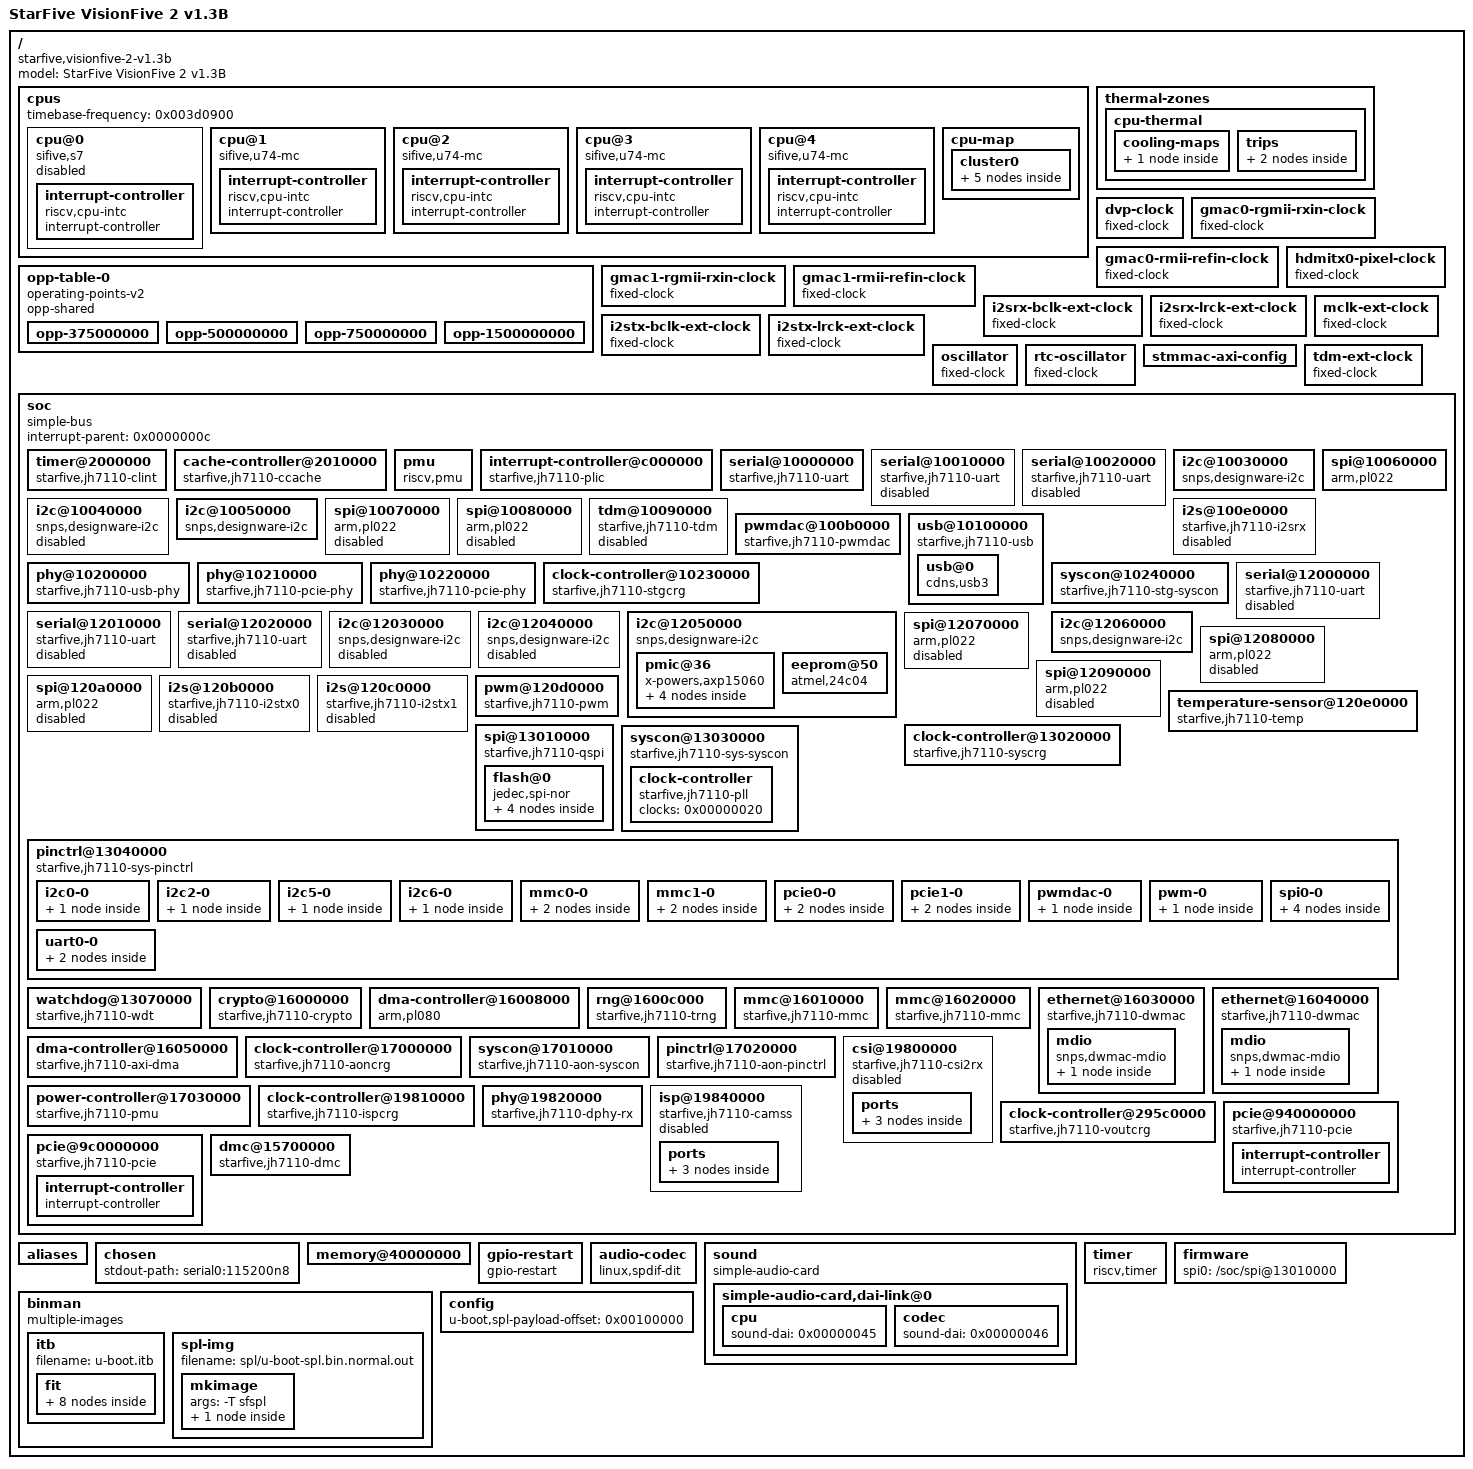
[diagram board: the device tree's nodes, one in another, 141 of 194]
//这个玩意来自于mainline
/dts-v1/;
// magic:		0xd00dfeed
// totalsize:		0xb18d (45453)
// off_dt_struct:	0x78
// off_dt_strings:	0x9234
// off_mem_rsvmap:	0x28
// version:		17
// last_comp_version:	16
// boot_cpuid_phys:	0x0
// size_dt_strings:	0xf59
// size_dt_struct:	0x91bc

/ {
    compatible = "starfive,visionfive-2-v1.3b", "starfive,jh7110";
    #address-cells = <0x00000002>;
    #size-cells = <0x00000002>;
    model = "StarFive VisionFive 2 v1.3B";
    cpus {
        #address-cells = <0x00000001>;
        #size-cells = <0x00000000>;
        timebase-frequency = <0x003d0900>;
        bootph-pre-ram;
        phandle = <0x00000047>;
        cpu@0 {
            compatible = "sifive,s7", "riscv";
            reg = <0x00000000>;
            device_type = "cpu";
            i-cache-block-size = <0x00000040>;
            i-cache-sets = <0x00000040>;
            i-cache-size = <0x00004000>;
            next-level-cache = <0x00000001>;
            riscv,isa = "rv64imac_zba_zbb";
            riscv,isa-base = "rv64i";
            riscv,isa-extensions = "i", "m", "a", "c", "zba", "zbb", "zicntr", "zicsr", "zifencei", "zihpm";
            status = "disabled";
            phandle = <0x00000005>;
            interrupt-controller {
                compatible = "riscv,cpu-intc";
                interrupt-controller;
                #interrupt-cells = <0x00000001>;
                bootph-pre-ram;
                phandle = <0x0000000d>;
            };
        };
        cpu@1 {
            compatible = "sifive,u74-mc", "riscv";
            reg = <0x00000001>;
            d-cache-block-size = <0x00000040>;
            d-cache-sets = <0x00000040>;
            d-cache-size = <0x00008000>;
            d-tlb-sets = <0x00000001>;
            d-tlb-size = <0x00000028>;
            device_type = "cpu";
            i-cache-block-size = <0x00000040>;
            i-cache-sets = <0x00000040>;
            i-cache-size = <0x00008000>;
            i-tlb-sets = <0x00000001>;
            i-tlb-size = <0x00000028>;
            mmu-type = "riscv,sv39";
            next-level-cache = <0x00000001>;
            riscv,isa = "rv64imafdc_zba_zbb";
            riscv,isa-base = "rv64i";
            riscv,isa-extensions = "i", "m", "a", "f", "d", "c", "zba", "zbb", "zicntr", "zicsr", "zifencei", "zihpm";
            tlb-split;
            operating-points-v2 = <0x00000002>;
            clocks = <0x00000003 0x00000001>;
            clock-names = "cpu";
            #cooling-cells = <0x00000002>;
            cpu-supply = <0x00000004>;
            phandle = <0x00000006>;
            interrupt-controller {
                compatible = "riscv,cpu-intc";
                interrupt-controller;
                #interrupt-cells = <0x00000001>;
                bootph-pre-ram;
                phandle = <0x0000000e>;
            };
        };
        cpu@2 {
            compatible = "sifive,u74-mc", "riscv";
            reg = <0x00000002>;
            d-cache-block-size = <0x00000040>;
            d-cache-sets = <0x00000040>;
            d-cache-size = <0x00008000>;
            d-tlb-sets = <0x00000001>;
            d-tlb-size = <0x00000028>;
            device_type = "cpu";
            i-cache-block-size = <0x00000040>;
            i-cache-sets = <0x00000040>;
            i-cache-size = <0x00008000>;
            i-tlb-sets = <0x00000001>;
            i-tlb-size = <0x00000028>;
            mmu-type = "riscv,sv39";
            next-level-cache = <0x00000001>;
            riscv,isa = "rv64imafdc_zba_zbb";
            riscv,isa-base = "rv64i";
            riscv,isa-extensions = "i", "m", "a", "f", "d", "c", "zba", "zbb", "zicntr", "zicsr", "zifencei", "zihpm";
            tlb-split;
            operating-points-v2 = <0x00000002>;
            clocks = <0x00000003 0x00000001>;
            clock-names = "cpu";
            #cooling-cells = <0x00000002>;
            cpu-supply = <0x00000004>;
            phandle = <0x00000007>;
            interrupt-controller {
                compatible = "riscv,cpu-intc";
                interrupt-controller;
                #interrupt-cells = <0x00000001>;
                bootph-pre-ram;
                phandle = <0x0000000f>;
            };
        };
        cpu@3 {
            compatible = "sifive,u74-mc", "riscv";
            reg = <0x00000003>;
            d-cache-block-size = <0x00000040>;
            d-cache-sets = <0x00000040>;
            d-cache-size = <0x00008000>;
            d-tlb-sets = <0x00000001>;
            d-tlb-size = <0x00000028>;
            device_type = "cpu";
            i-cache-block-size = <0x00000040>;
            i-cache-sets = <0x00000040>;
            i-cache-size = <0x00008000>;
            i-tlb-sets = <0x00000001>;
            i-tlb-size = <0x00000028>;
            mmu-type = "riscv,sv39";
            next-level-cache = <0x00000001>;
            riscv,isa = "rv64imafdc_zba_zbb";
            riscv,isa-base = "rv64i";
            riscv,isa-extensions = "i", "m", "a", "f", "d", "c", "zba", "zbb", "zicntr", "zicsr", "zifencei", "zihpm";
            tlb-split;
            operating-points-v2 = <0x00000002>;
            clocks = <0x00000003 0x00000001>;
            clock-names = "cpu";
            #cooling-cells = <0x00000002>;
            cpu-supply = <0x00000004>;
            phandle = <0x00000008>;
            interrupt-controller {
                compatible = "riscv,cpu-intc";
                interrupt-controller;
                #interrupt-cells = <0x00000001>;
                bootph-pre-ram;
                phandle = <0x00000010>;
            };
        };
        cpu@4 {
            compatible = "sifive,u74-mc", "riscv";
            reg = <0x00000004>;
            d-cache-block-size = <0x00000040>;
            d-cache-sets = <0x00000040>;
            d-cache-size = <0x00008000>;
            d-tlb-sets = <0x00000001>;
            d-tlb-size = <0x00000028>;
            device_type = "cpu";
            i-cache-block-size = <0x00000040>;
            i-cache-sets = <0x00000040>;
            i-cache-size = <0x00008000>;
            i-tlb-sets = <0x00000001>;
            i-tlb-size = <0x00000028>;
            mmu-type = "riscv,sv39";
            next-level-cache = <0x00000001>;
            riscv,isa = "rv64imafdc_zba_zbb";
            riscv,isa-base = "rv64i";
            riscv,isa-extensions = "i", "m", "a", "f", "d", "c", "zba", "zbb", "zicntr", "zicsr", "zifencei", "zihpm";
            tlb-split;
            operating-points-v2 = <0x00000002>;
            clocks = <0x00000003 0x00000001>;
            clock-names = "cpu";
            #cooling-cells = <0x00000002>;
            cpu-supply = <0x00000004>;
            phandle = <0x00000009>;
            interrupt-controller {
                compatible = "riscv,cpu-intc";
                interrupt-controller;
                #interrupt-cells = <0x00000001>;
                bootph-pre-ram;
                phandle = <0x00000011>;
            };
        };
        cpu-map {
            cluster0 {
                core0 {
                    cpu = <0x00000005>;
                };
                core1 {
                    cpu = <0x00000006>;
                };
                core2 {
                    cpu = <0x00000007>;
                };
                core3 {
                    cpu = <0x00000008>;
                };
                core4 {
                    cpu = <0x00000009>;
                };
            };
        };
    };
    opp-table-0 {
        compatible = "operating-points-v2";
        opp-shared;
        phandle = <0x00000002>;
        opp-375000000 {
            opp-hz = <0x00000000 0x165a0bc0>;
            opp-microvolt = <0x000c3500>;
        };
        opp-500000000 {
            opp-hz = <0x00000000 0x1dcd6500>;
            opp-microvolt = <0x000c3500>;
        };
        opp-750000000 {
            opp-hz = <0x00000000 0x2cb41780>;
            opp-microvolt = <0x000c3500>;
        };
        opp-1500000000 {
            opp-hz = <0x00000000 0x59682f00>;
            opp-microvolt = <0x000fde80>;
        };
    };
    thermal-zones {
        cpu-thermal {
            polling-delay-passive = <0x000000fa>;
            polling-delay = <0x00003a98>;
            thermal-sensors = <0x0000000a>;
            cooling-maps {
                map0 {
                    trip = <0x0000000b>;
                    cooling-device = <0x00000006 0xffffffff 0xffffffff 0x00000007 0xffffffff 0xffffffff 0x00000008 0xffffffff 0xffffffff 0x00000009 0xffffffff 0xffffffff>;
                };
            };
            trips {
                cpu-alert0 {
                    temperature = <0x00014c08>;
                    hysteresis = <0x000007d0>;
                    type = "passive";
                    phandle = <0x0000000b>;
                };
                cpu-crit {
                    temperature = <0x000186a0>;
                    hysteresis = <0x000007d0>;
                    type = "critical";
                };
            };
        };
    };
    dvp-clock {
        compatible = "fixed-clock";
        clock-output-names = "dvp_clk";
        #clock-cells = <0x00000000>;
        clock-frequency = <0x046cf710>;
        phandle = <0x0000003a>;
    };
    gmac0-rgmii-rxin-clock {
        compatible = "fixed-clock";
        clock-output-names = "gmac0_rgmii_rxin";
        #clock-cells = <0x00000000>;
        clock-frequency = <0x07735940>;
        bootph-pre-ram;
        phandle = <0x00000035>;
    };
    gmac0-rmii-refin-clock {
        compatible = "fixed-clock";
        clock-output-names = "gmac0_rmii_refin";
        #clock-cells = <0x00000000>;
        clock-frequency = <0x02faf080>;
        bootph-pre-ram;
        phandle = <0x00000034>;
    };
    gmac1-rgmii-rxin-clock {
        compatible = "fixed-clock";
        clock-output-names = "gmac1_rgmii_rxin";
        #clock-cells = <0x00000000>;
        clock-frequency = <0x07735940>;
        bootph-pre-ram;
        phandle = <0x00000027>;
    };
    gmac1-rmii-refin-clock {
        compatible = "fixed-clock";
        clock-output-names = "gmac1_rmii_refin";
        #clock-cells = <0x00000000>;
        clock-frequency = <0x02faf080>;
        bootph-pre-ram;
        phandle = <0x00000026>;
    };
    hdmitx0-pixel-clock {
        compatible = "fixed-clock";
        clock-output-names = "hdmitx0_pixelclk";
        #clock-cells = <0x00000000>;
        clock-frequency = <0x11b3dc40>;
        phandle = <0x0000003d>;
    };
    i2srx-bclk-ext-clock {
        compatible = "fixed-clock";
        clock-output-names = "i2srx_bclk_ext";
        #clock-cells = <0x00000000>;
        clock-frequency = <0x00bb8000>;
        phandle = <0x00000019>;
    };
    i2srx-lrck-ext-clock {
        compatible = "fixed-clock";
        clock-output-names = "i2srx_lrck_ext";
        #clock-cells = <0x00000000>;
        clock-frequency = <0x0002ee00>;
        phandle = <0x0000001a>;
    };
    i2stx-bclk-ext-clock {
        compatible = "fixed-clock";
        clock-output-names = "i2stx_bclk_ext";
        #clock-cells = <0x00000000>;
        clock-frequency = <0x00bb8000>;
        phandle = <0x00000023>;
    };
    i2stx-lrck-ext-clock {
        compatible = "fixed-clock";
        clock-output-names = "i2stx_lrck_ext";
        #clock-cells = <0x00000000>;
        clock-frequency = <0x0002ee00>;
        phandle = <0x00000024>;
    };
    mclk-ext-clock {
        compatible = "fixed-clock";
        clock-output-names = "mclk_ext";
        #clock-cells = <0x00000000>;
        clock-frequency = <0x00bb8000>;
        phandle = <0x00000018>;
    };
    oscillator {
        compatible = "fixed-clock";
        clock-output-names = "osc";
        #clock-cells = <0x00000000>;
        clock-frequency = <0x016e3600>;
        bootph-pre-ram;
        phandle = <0x00000020>;
    };
    rtc-oscillator {
        compatible = "fixed-clock";
        clock-output-names = "rtc_osc";
        #clock-cells = <0x00000000>;
        clock-frequency = <0x00008000>;
        phandle = <0x00000036>;
    };
    stmmac-axi-config {
        snps,lpi_en;
        snps,wr_osr_lmt = <0x0000000f>;
        snps,rd_osr_lmt = <0x0000000f>;
        snps,blen = <0x00000100 0x00000080 0x00000040 0x00000020 0x00000000 0x00000000 0x00000000>;
        phandle = <0x00000030>;
    };
    tdm-ext-clock {
        compatible = "fixed-clock";
        clock-output-names = "tdm_ext";
        #clock-cells = <0x00000000>;
        clock-frequency = <0x02ee0000>;
        phandle = <0x00000016>;
    };
    soc {
        compatible = "simple-bus";
        interrupt-parent = <0x0000000c>;
        #address-cells = <0x00000002>;
        #size-cells = <0x00000002>;
        ranges;
        bootph-pre-ram;
        timer@2000000 {
            compatible = "starfive,jh7110-clint", "sifive,clint0";
            reg = <0x00000000 0x02000000 0x00000000 0x00010000>;
            interrupts-extended = <0x0000000d 0x00000003 0x0000000d 0x00000007 0x0000000e 0x00000003 0x0000000e 0x00000007 0x0000000f 0x00000003 0x0000000f 0x00000007 0x00000010 0x00000003 0x00000010 0x00000007 0x00000011 0x00000003 0x00000011 0x00000007>;
            bootph-pre-ram;
            phandle = <0x00000048>;
        };
        cache-controller@2010000 {
            compatible = "starfive,jh7110-ccache", "sifive,ccache0", "cache";
            reg = <0x00000000 0x02010000 0x00000000 0x00004000>;
            interrupts = <0x00000001 0x00000003 0x00000004 0x00000002>;
            cache-block-size = <0x00000040>;
            cache-level = <0x00000002>;
            cache-sets = <0x00000800>;
            cache-size = <0x00200000>;
            cache-unified;
            phandle = <0x00000001>;
        };
        pmu {
            compatible = "riscv,pmu";
            riscv,event-to-mhpmcounters = <0x00000005 0x00000006 0x00000018>;
            riscv,event-to-mhpmevent = <0x00000005 0x00000000 0x00004000 0x00000006 0x00000000 0x00004001>;
            riscv,raw-event-to-mhpmcounters = <0x00000000 0x00000100 0xffffffff 0xffffffff 0x00000018 0x00000000 0x00000200 0xffffffff 0xffffffff 0x00000018 0x00000000 0x00000400 0xffffffff 0xffffffff 0x00000018 0x00000000 0x00000800 0xffffffff 0xffffffff 0x00000018 0x00000000 0x00001000 0xffffffff 0xffffffff 0x00000018 0x00000000 0x00002000 0xffffffff 0xffffffff 0x00000018 0x00000000 0x00004000 0xffffffff 0xffffffff 0x00000018 0x00000000 0x00008000 0xffffffff 0xffffffff 0x00000018 0x00000000 0x00010000 0xffffffff 0xffffffff 0x00000018 0x00000000 0x00020000 0xffffffff 0xffffffff 0x00000018 0x00000000 0x00040000 0xffffffff 0xffffffff 0x00000018 0x00000000 0x00080000 0xffffffff 0xffffffff 0x00000018 0x00000000 0x00100000 0xffffffff 0xffffffff 0x00000018 0x00000000 0x00200000 0xffffffff 0xffffffff 0x00000018 0x00000000 0x00400000 0xffffffff 0xffffffff 0x00000018 0x00000000 0x00800000 0xffffffff 0xffffffff 0x00000018 0x00000000 0x01000000 0xffffffff 0xffffffff 0x00000018 0x00000000 0x02000000 0xffffffff 0xffffffff 0x00000018 0x00000000 0x00000101 0xffffffff 0xffffffff 0x00000018 0x00000000 0x00000201 0xffffffff 0xffffffff 0x00000018 0x00000000 0x00000401 0xffffffff 0xffffffff 0x00000018 0x00000000 0x00000801 0xffffffff 0xffffffff 0x00000018 0x00000000 0x00001001 0xffffffff 0xffffffff 0x00000018 0x00000000 0x00002001 0xffffffff 0xffffffff 0x00000018 0x00000000 0x00004001 0xffffffff 0xffffffff 0x00000018 0x00000000 0x00008001 0xffffffff 0xffffffff 0x00000018 0x00000000 0x00010001 0xffffffff 0xffffffff 0x00000018 0x00000000 0x00020001 0xffffffff 0xffffffff 0x00000018 0x00000000 0x00040001 0xffffffff 0xffffffff 0x00000018 0x00000000 0x00000102 0xffffffff 0xffffffff 0x00000018 0x00000000 0x00000202 0xffffffff 0xffffffff 0x00000018 0x00000000 0x00000402 0xffffffff 0xffffffff 0x00000018 0x00000000 0x00000802 0xffffffff 0xffffffff 0x00000018 0x00000000 0x00001002 0xffffffff 0xffffffff 0x00000018 0x00000000 0x00002002 0xffffffff 0xffffffff 0x00000018>;
        };
        interrupt-controller@c000000 {
            compatible = "starfive,jh7110-plic", "sifive,plic-1.0.0";
            reg = <0x00000000 0x0c000000 0x00000000 0x04000000>;
            interrupts-extended = <0x0000000d 0x0000000b 0x0000000e 0x0000000b 0x0000000e 0x00000009 0x0000000f 0x0000000b 0x0000000f 0x00000009 0x00000010 0x0000000b 0x00000010 0x00000009 0x00000011 0x0000000b 0x00000011 0x00000009>;
            interrupt-controller;
            #interrupt-cells = <0x00000001>;
            #address-cells = <0x00000000>;
            riscv,ndev = <0x00000088>;
            phandle = <0x0000000c>;
        };
        serial@10000000 {
            compatible = "starfive,jh7110-uart", "snps,dw-apb-uart";
            reg = <0x00000000 0x10000000 0x00000000 0x00010000>;
            clocks = <0x00000003 0x00000092 0x00000003 0x00000091>;
            clock-names = "baudclk", "apb_pclk";
            resets = <0x00000003 0x00000053 0x00000003 0x00000054>;
            interrupts = <0x00000020>;
            reg-io-width = <0x00000004>;
            reg-shift = <0x00000002>;
            status = "okay";
            pinctrl-names = "default";
            pinctrl-0 = <0x00000012>;
            bootph-pre-ram;
            reg-offset = <0x00000000>;
            current-speed = <0x0001c200>;
            phandle = <0x00000049>;
        };
        serial@10010000 {
            compatible = "starfive,jh7110-uart", "snps,dw-apb-uart";
            reg = <0x00000000 0x10010000 0x00000000 0x00010000>;
            clocks = <0x00000003 0x00000094 0x00000003 0x00000093>;
            clock-names = "baudclk", "apb_pclk";
            resets = <0x00000003 0x00000055 0x00000003 0x00000056>;
            interrupts = <0x00000021>;
            reg-io-width = <0x00000004>;
            reg-shift = <0x00000002>;
            status = "disabled";
            phandle = <0x0000004a>;
        };
        serial@10020000 {
            compatible = "starfive,jh7110-uart", "snps,dw-apb-uart";
            reg = <0x00000000 0x10020000 0x00000000 0x00010000>;
            clocks = <0x00000003 0x00000096 0x00000003 0x00000095>;
            clock-names = "baudclk", "apb_pclk";
            resets = <0x00000003 0x00000057 0x00000003 0x00000058>;
            interrupts = <0x00000022>;
            reg-io-width = <0x00000004>;
            reg-shift = <0x00000002>;
            status = "disabled";
            phandle = <0x0000004b>;
        };
        i2c@10030000 {
            compatible = "snps,designware-i2c";
            reg = <0x00000000 0x10030000 0x00000000 0x00010000>;
            clocks = <0x00000003 0x0000008a>;
            clock-names = "ref";
            resets = <0x00000003 0x0000004c>;
            interrupts = <0x00000023>;
            #address-cells = <0x00000001>;
            #size-cells = <0x00000000>;
            status = "okay";
            clock-frequency = <0x000186a0>;
            i2c-sda-hold-time-ns = <0x0000012c>;
            i2c-sda-falling-time-ns = <0x000001fe>;
            i2c-scl-falling-time-ns = <0x000001fe>;
            pinctrl-names = "default";
            pinctrl-0 = <0x00000013>;
            phandle = <0x0000004c>;
        };
        i2c@10040000 {
            compatible = "snps,designware-i2c";
            reg = <0x00000000 0x10040000 0x00000000 0x00010000>;
            clocks = <0x00000003 0x0000008b>;
            clock-names = "ref";
            resets = <0x00000003 0x0000004d>;
            interrupts = <0x00000024>;
            #address-cells = <0x00000001>;
            #size-cells = <0x00000000>;
            status = "disabled";
            phandle = <0x0000004d>;
        };
        i2c@10050000 {
            compatible = "snps,designware-i2c";
            reg = <0x00000000 0x10050000 0x00000000 0x00010000>;
            clocks = <0x00000003 0x0000008c>;
            clock-names = "ref";
            resets = <0x00000003 0x0000004e>;
            interrupts = <0x00000025>;
            #address-cells = <0x00000001>;
            #size-cells = <0x00000000>;
            status = "okay";
            clock-frequency = <0x000186a0>;
            i2c-sda-hold-time-ns = <0x0000012c>;
            i2c-sda-falling-time-ns = <0x000001fe>;
            i2c-scl-falling-time-ns = <0x000001fe>;
            pinctrl-names = "default";
            pinctrl-0 = <0x00000014>;
            phandle = <0x0000004e>;
        };
        spi@10060000 {
            compatible = "arm,pl022", "arm,primecell";
            reg = <0x00000000 0x10060000 0x00000000 0x00010000>;
            clocks = <0x00000003 0x00000083 0x00000003 0x00000083>;
            clock-names = "sspclk", "apb_pclk";
            resets = <0x00000003 0x00000045>;
            interrupts = <0x00000026>;
            arm,primecell-periphid = <0x00041022>;
            num-cs = <0x00000001>;
            #address-cells = <0x00000001>;
            #size-cells = <0x00000000>;
            status = "okay";
            pinctrl-names = "default";
            pinctrl-0 = <0x00000015>;
            phandle = <0x0000004f>;
        };
        spi@10070000 {
            compatible = "arm,pl022", "arm,primecell";
            reg = <0x00000000 0x10070000 0x00000000 0x00010000>;
            clocks = <0x00000003 0x00000084 0x00000003 0x00000084>;
            clock-names = "sspclk", "apb_pclk";
            resets = <0x00000003 0x00000046>;
            interrupts = <0x00000027>;
            arm,primecell-periphid = <0x00041022>;
            num-cs = <0x00000001>;
            #address-cells = <0x00000001>;
            #size-cells = <0x00000000>;
            status = "disabled";
            phandle = <0x00000050>;
        };
        spi@10080000 {
            compatible = "arm,pl022", "arm,primecell";
            reg = <0x00000000 0x10080000 0x00000000 0x00010000>;
            clocks = <0x00000003 0x00000085 0x00000003 0x00000085>;
            clock-names = "sspclk", "apb_pclk";
            resets = <0x00000003 0x00000047>;
            interrupts = <0x00000028>;
            arm,primecell-periphid = <0x00041022>;
            num-cs = <0x00000001>;
            #address-cells = <0x00000001>;
            #size-cells = <0x00000000>;
            status = "disabled";
            phandle = <0x00000051>;
        };
        tdm@10090000 {
            compatible = "starfive,jh7110-tdm";
            reg = <0x00000000 0x10090000 0x00000000 0x00001000>;
            clocks = <0x00000003 0x000000b8 0x00000003 0x000000b9 0x00000003 0x000000ba 0x00000003 0x000000bb 0x00000003 0x00000011 0x00000016>;
            clock-names = "tdm_ahb", "tdm_apb", "tdm_internal", "tdm", "mclk_inner", "tdm_ext";
            resets = <0x00000003 0x00000069 0x00000003 0x0000006b 0x00000003 0x0000006a>;
            dmas = <0x00000017 0x00000014 0x00000017 0x00000015>;
            dma-names = "rx", "tx";
            #sound-dai-cells = <0x00000000>;
            status = "disabled";
            phandle = <0x00000052>;
        };
        i2s@100e0000 {
            compatible = "starfive,jh7110-i2srx";
            reg = <0x00000000 0x100e0000 0x00000000 0x00001000>;
            clocks = <0x00000003 0x000000b0 0x00000003 0x000000af 0x00000003 0x00000012 0x00000003 0x00000011 0x00000018 0x00000003 0x000000b3 0x00000003 0x000000b5 0x00000019 0x0000001a>;
            clock-names = "i2sclk", "apb", "mclk", "mclk_inner", "mclk_ext", "bclk", "lrck", "bclk_ext", "lrck_ext";
            resets = <0x00000003 0x00000063 0x00000003 0x00000064>;
            dmas = <0x00000000 0x00000017 0x00000018>;
            dma-names = "tx", "rx";
            starfive,syscon = <0x0000001b 0x00000018 0x00000002>;
            #sound-dai-cells = <0x00000000>;
            status = "disabled";
            phandle = <0x00000053>;
        };
        pwmdac@100b0000 {
            compatible = "starfive,jh7110-pwmdac";
            reg = <0x00000000 0x100b0000 0x00000000 0x00001000>;
            clocks = <0x00000003 0x0000009d 0x00000003 0x0000009e>;
            clock-names = "apb", "core";
            resets = <0x00000003 0x00000060>;
            dmas = <0x00000017 0x00000016>;
            dma-names = "tx";
            #sound-dai-cells = <0x00000000>;
            status = "okay";
            pinctrl-names = "default";
            pinctrl-0 = <0x0000001c>;
            phandle = <0x00000045>;
        };
        usb@10100000 {
            compatible = "starfive,jh7110-usb";
            ranges = <0x00000000 0x00000000 0x10100000 0x00100000>;
            #address-cells = <0x00000001>;
            #size-cells = <0x00000001>;
            starfive,stg-syscon = <0x0000001d 0x00000004>;
            clocks = <0x0000001e 0x00000004 0x0000001e 0x00000005 0x0000001e 0x00000001 0x0000001e 0x00000003 0x0000001e 0x00000002>;
            clock-names = "lpm", "stb", "apb", "axi", "utmi_apb";
            resets = <0x0000001e 0x0000000a 0x0000001e 0x00000008 0x0000001e 0x00000007 0x0000001e 0x00000009>;
            reset-names = "pwrup", "apb", "axi", "utmi_apb";
            status = "okay";
            dr_mode = "peripheral";
            phandle = <0x00000054>;
            usb@0 {
                compatible = "cdns,usb3";
                reg = <0x00000000 0x00010000 0x00010000 0x00010000 0x00020000 0x00010000>;
                reg-names = "otg", "xhci", "dev";
                interrupts = <0x00000064 0x0000006c 0x0000006e>;
                interrupt-names = "host", "peripheral", "otg";
                phys = <0x0000001f>;
                phy-names = "cdns3,usb2-phy";
                phandle = <0x00000055>;
            };
        };
        phy@10200000 {
            compatible = "starfive,jh7110-usb-phy";
            reg = <0x00000000 0x10200000 0x00000000 0x00010000>;
            clocks = <0x00000003 0x0000005f 0x0000001e 0x00000006>;
            clock-names = "125m", "app_125m";
            #phy-cells = <0x00000000>;
            phandle = <0x0000001f>;
        };
        phy@10210000 {
            compatible = "starfive,jh7110-pcie-phy";
            reg = <0x00000000 0x10210000 0x00000000 0x00010000>;
            starfive,sys-syscon = <0x0000001b 0x00000018>;
            starfive,stg-syscon = <0x0000001d 0x00000148 0x000001f4>;
            #phy-cells = <0x00000000>;
            phandle = <0x0000003f>;
        };
        phy@10220000 {
            compatible = "starfive,jh7110-pcie-phy";
            reg = <0x00000000 0x10220000 0x00000000 0x00010000>;
            #phy-cells = <0x00000000>;
            phandle = <0x00000042>;
        };
        clock-controller@10230000 {
            compatible = "starfive,jh7110-stgcrg";
            reg = <0x00000000 0x10230000 0x00000000 0x00010000>;
            clocks = <0x00000020 0x00000003 0x00000036 0x00000003 0x00000008 0x00000003 0x0000005f 0x00000003 0x00000002 0x00000003 0x00000037 0x00000003 0x00000006 0x00000003 0x0000000b>;
            clock-names = "osc", "hifi4_core", "stg_axiahb", "usb_125m", "cpu_bus", "hifi4_axi", "nocstg_bus", "apb_bus";
            #clock-cells = <0x00000001>;
            #reset-cells = <0x00000001>;
            bootph-pre-ram;
            phandle = <0x0000001e>;
        };
        syscon@10240000 {
            compatible = "starfive,jh7110-stg-syscon", "syscon";
            reg = <0x00000000 0x10240000 0x00000000 0x00001000>;
            phandle = <0x0000001d>;
        };
        serial@12000000 {
            compatible = "starfive,jh7110-uart", "snps,dw-apb-uart";
            reg = <0x00000000 0x12000000 0x00000000 0x00010000>;
            clocks = <0x00000003 0x00000098 0x00000003 0x00000097>;
            clock-names = "baudclk", "apb_pclk";
            resets = <0x00000003 0x00000059 0x00000003 0x0000005a>;
            interrupts = <0x0000002d>;
            reg-io-width = <0x00000004>;
            reg-shift = <0x00000002>;
            status = "disabled";
            phandle = <0x00000056>;
        };
        serial@12010000 {
            compatible = "starfive,jh7110-uart", "snps,dw-apb-uart";
            reg = <0x00000000 0x12010000 0x00000000 0x00010000>;
            clocks = <0x00000003 0x0000009a 0x00000003 0x00000099>;
            clock-names = "baudclk", "apb_pclk";
            resets = <0x00000003 0x0000005b 0x00000003 0x0000005c>;
            interrupts = <0x0000002e>;
            reg-io-width = <0x00000004>;
            reg-shift = <0x00000002>;
            status = "disabled";
            phandle = <0x00000057>;
        };
        serial@12020000 {
            compatible = "starfive,jh7110-uart", "snps,dw-apb-uart";
            reg = <0x00000000 0x12020000 0x00000000 0x00010000>;
            clocks = <0x00000003 0x0000009c 0x00000003 0x0000009b>;
            clock-names = "baudclk", "apb_pclk";
            resets = <0x00000003 0x0000005d 0x00000003 0x0000005e>;
            interrupts = <0x0000002f>;
            reg-io-width = <0x00000004>;
            reg-shift = <0x00000002>;
            status = "disabled";
            phandle = <0x00000058>;
        };
        i2c@12030000 {
            compatible = "snps,designware-i2c";
            reg = <0x00000000 0x12030000 0x00000000 0x00010000>;
            clocks = <0x00000003 0x0000008d>;
            clock-names = "ref";
            resets = <0x00000003 0x0000004f>;
            interrupts = <0x00000030>;
            #address-cells = <0x00000001>;
            #size-cells = <0x00000000>;
            status = "disabled";
            phandle = <0x00000059>;
        };
        i2c@12040000 {
            compatible = "snps,designware-i2c";
            reg = <0x00000000 0x12040000 0x00000000 0x00010000>;
            clocks = <0x00000003 0x0000008e>;
            clock-names = "ref";
            resets = <0x00000003 0x00000050>;
            interrupts = <0x00000031>;
            #address-cells = <0x00000001>;
            #size-cells = <0x00000000>;
            status = "disabled";
            phandle = <0x0000005a>;
        };
        i2c@12050000 {
            compatible = "snps,designware-i2c";
            reg = <0x00000000 0x12050000 0x00000000 0x00010000>;
            clocks = <0x00000003 0x0000008f>;
            clock-names = "ref";
            resets = <0x00000003 0x00000051>;
            interrupts = <0x00000032>;
            #address-cells = <0x00000001>;
            #size-cells = <0x00000000>;
            status = "okay";
            clock-frequency = <0x000186a0>;
            i2c-sda-hold-time-ns = <0x0000012c>;
            i2c-sda-falling-time-ns = <0x000001fe>;
            i2c-scl-falling-time-ns = <0x000001fe>;
            pinctrl-names = "default";
            pinctrl-0 = <0x00000021>;
            bootph-pre-ram;
            phandle = <0x0000005b>;
            pmic@36 {
                compatible = "x-powers,axp15060";
                reg = <0x00000036>;
                interrupt-controller;
                #interrupt-cells = <0x00000001>;
                phandle = <0x0000005c>;
                regulators {
                    dcdc1 {
                        regulator-boot-on;
                        regulator-always-on;
                        regulator-min-microvolt = <0x00325aa0>;
                        regulator-max-microvolt = <0x00325aa0>;
                        regulator-name = "vcc_3v3";
                        phandle = <0x0000002b>;
                    };
                    dcdc2 {
                        regulator-always-on;
                        regulator-min-microvolt = <0x0007a120>;
                        regulator-max-microvolt = <0x00177fa0>;
                        regulator-name = "vdd_cpu";
                        phandle = <0x00000004>;
                    };
                    aldo4 {
                        regulator-boot-on;
                        regulator-always-on;
                        regulator-min-microvolt = <0x001b7740>;
                        regulator-max-microvolt = <0x00325aa0>;
                        regulator-name = "emmc_vdd";
                        phandle = <0x0000002c>;
                    };
                };
            };
            eeprom@50 {
                bootph-pre-ram;
                compatible = "atmel,24c04";
                reg = <0x00000050>;
                pagesize = <0x00000010>;
            };
        };
        i2c@12060000 {
            compatible = "snps,designware-i2c";
            reg = <0x00000000 0x12060000 0x00000000 0x00010000>;
            clocks = <0x00000003 0x00000090>;
            clock-names = "ref";
            resets = <0x00000003 0x00000052>;
            interrupts = <0x00000033>;
            #address-cells = <0x00000001>;
            #size-cells = <0x00000000>;
            status = "okay";
            clock-frequency = <0x000186a0>;
            i2c-sda-hold-time-ns = <0x0000012c>;
            i2c-sda-falling-time-ns = <0x000001fe>;
            i2c-scl-falling-time-ns = <0x000001fe>;
            pinctrl-names = "default";
            pinctrl-0 = <0x00000022>;
            phandle = <0x0000005d>;
        };
        spi@12070000 {
            compatible = "arm,pl022", "arm,primecell";
            reg = <0x00000000 0x12070000 0x00000000 0x00010000>;
            clocks = <0x00000003 0x00000086 0x00000003 0x00000086>;
            clock-names = "sspclk", "apb_pclk";
            resets = <0x00000003 0x00000048>;
            interrupts = <0x00000034>;
            arm,primecell-periphid = <0x00041022>;
            num-cs = <0x00000001>;
            #address-cells = <0x00000001>;
            #size-cells = <0x00000000>;
            status = "disabled";
            phandle = <0x0000005e>;
        };
        spi@12080000 {
            compatible = "arm,pl022", "arm,primecell";
            reg = <0x00000000 0x12080000 0x00000000 0x00010000>;
            clocks = <0x00000003 0x00000087 0x00000003 0x00000087>;
            clock-names = "sspclk", "apb_pclk";
            resets = <0x00000003 0x00000049>;
            interrupts = <0x00000035>;
            arm,primecell-periphid = <0x00041022>;
            num-cs = <0x00000001>;
            #address-cells = <0x00000001>;
            #size-cells = <0x00000000>;
            status = "disabled";
            phandle = <0x0000005f>;
        };
        spi@12090000 {
            compatible = "arm,pl022", "arm,primecell";
            reg = <0x00000000 0x12090000 0x00000000 0x00010000>;
            clocks = <0x00000003 0x00000088 0x00000003 0x00000088>;
            clock-names = "sspclk", "apb_pclk";
            resets = <0x00000003 0x0000004a>;
            interrupts = <0x00000036>;
            arm,primecell-periphid = <0x00041022>;
            num-cs = <0x00000001>;
            #address-cells = <0x00000001>;
            #size-cells = <0x00000000>;
            status = "disabled";
            phandle = <0x00000060>;
        };
        spi@120a0000 {
            compatible = "arm,pl022", "arm,primecell";
            reg = <0x00000000 0x120a0000 0x00000000 0x00010000>;
            clocks = <0x00000003 0x00000089 0x00000003 0x00000089>;
            clock-names = "sspclk", "apb_pclk";
            resets = <0x00000003 0x0000004b>;
            interrupts = <0x00000037>;
            arm,primecell-periphid = <0x00041022>;
            num-cs = <0x00000001>;
            #address-cells = <0x00000001>;
            #size-cells = <0x00000000>;
            status = "disabled";
            phandle = <0x00000061>;
        };
        i2s@120b0000 {
            compatible = "starfive,jh7110-i2stx0";
            reg = <0x00000000 0x120b0000 0x00000000 0x00001000>;
            clocks = <0x00000003 0x000000a2 0x00000003 0x000000a1 0x00000003 0x00000012 0x00000003 0x00000011 0x00000018>;
            clock-names = "i2sclk", "apb", "mclk", "mclk_inner", "mclk_ext";
            resets = <0x00000003 0x00000065 0x00000003 0x00000066>;
            dmas = <0x00000017 0x0000002f>;
            dma-names = "tx";
            #sound-dai-cells = <0x00000000>;
            status = "disabled";
            phandle = <0x00000062>;
        };
        i2s@120c0000 {
            compatible = "starfive,jh7110-i2stx1";
            reg = <0x00000000 0x120c0000 0x00000000 0x00001000>;
            clocks = <0x00000003 0x000000a9 0x00000003 0x000000a8 0x00000003 0x00000012 0x00000003 0x00000011 0x00000018 0x00000003 0x000000ac 0x00000003 0x000000ae 0x00000023 0x00000024>;
            clock-names = "i2sclk", "apb", "mclk", "mclk_inner", "mclk_ext", "bclk", "lrck", "bclk_ext", "lrck_ext";
            resets = <0x00000003 0x00000067 0x00000003 0x00000068>;
            dmas = <0x00000017 0x00000030>;
            dma-names = "tx";
            #sound-dai-cells = <0x00000000>;
            status = "disabled";
            phandle = <0x00000063>;
        };
        pwm@120d0000 {
            compatible = "starfive,jh7110-pwm", "opencores,pwm-v1";
            reg = <0x00000000 0x120d0000 0x00000000 0x00010000>;
            clocks = <0x00000003 0x00000079>;
            resets = <0x00000003 0x0000006c>;
            #pwm-cells = <0x00000003>;
            status = "okay";
            pinctrl-names = "default";
            pinctrl-0 = <0x00000025>;
            phandle = <0x00000064>;
        };
        temperature-sensor@120e0000 {
            compatible = "starfive,jh7110-temp";
            reg = <0x00000000 0x120e0000 0x00000000 0x00010000>;
            clocks = <0x00000003 0x00000082 0x00000003 0x00000081>;
            clock-names = "sense", "bus";
            resets = <0x00000003 0x0000007c 0x00000003 0x0000007b>;
            reset-names = "sense", "bus";
            #thermal-sensor-cells = <0x00000000>;
            phandle = <0x0000000a>;
        };
        spi@13010000 {
            compatible = "starfive,jh7110-qspi", "cdns,qspi-nor";
            reg = <0x00000000 0x13010000 0x00000000 0x00010000 0x00000000 0x21000000 0x00000000 0x00400000>;
            interrupts = <0x00000019>;
            clocks = <0x00000003 0x0000005a 0x00000003 0x00000057 0x00000003 0x00000058>;
            clock-names = "ref", "ahb", "apb";
            resets = <0x00000003 0x0000003e 0x00000003 0x0000003d 0x00000003 0x0000003f>;
            reset-names = "qspi", "qspi-ocp", "rstc_ref";
            cdns,fifo-depth = <0x00000100>;
            cdns,fifo-width = <0x00000004>;
            cdns,trigger-address = <0x00000000>;
            status = "okay";
            #address-cells = <0x00000001>;
            #size-cells = <0x00000000>;
            bootph-pre-ram;
            phandle = <0x00000065>;
            flash@0 {
                compatible = "jedec,spi-nor";
                reg = <0x00000000>;
                cdns,read-delay = <0x00000002>;
                spi-max-frequency = <0x05f5e100>;
                cdns,tshsl-ns = <0x00000001>;
                cdns,tsd2d-ns = <0x00000001>;
                cdns,tchsh-ns = <0x00000001>;
                cdns,tslch-ns = <0x00000001>;
                bootph-pre-ram;
                phandle = <0x00000066>;
                partitions {
                    compatible = "fixed-partitions";
                    #address-cells = <0x00000001>;
                    #size-cells = <0x00000001>;
                    spl@0 {
                        reg = <0x00000000 0x000f0000>;
                    };
                    uboot-env@f0000 {
                        reg = <0x000f0000 0x00010000>;
                    };
                    uboot@100000 {
                        reg = <0x00100000 0x00f00000>;
                    };
                };
            };
        };
        clock-controller@13020000 {
            compatible = "starfive,jh7110-syscrg";
            reg = <0x00000000 0x13020000 0x00000000 0x00010000>;
            clocks = <0x00000020 0x00000026 0x00000027 0x00000023 0x00000024 0x00000019 0x0000001a 0x00000016 0x00000018 0x00000028 0x00000000 0x00000028 0x00000001 0x00000028 0x00000002>;
            clock-names = "osc", "gmac1_rmii_refin", "gmac1_rgmii_rxin", "i2stx_bclk_ext", "i2stx_lrck_ext", "i2srx_bclk_ext", "i2srx_lrck_ext", "tdm_ext", "mclk_ext", "pll0_out", "pll1_out", "pll2_out";
            #clock-cells = <0x00000001>;
            #reset-cells = <0x00000001>;
            assigned-clocks = <0x00000003 0x00000000 0x00000003 0x00000005 0x00000003 0x00000004 0x00000003 0x0000005a>;
            assigned-clock-rates = <0x00000000 0x00000000 0x00000000 0x00000000>;
            bootph-pre-ram;
            assigned-clock-parents = <0x00000028 0x00000000 0x00000028 0x00000002 0x00000028 0x00000002 0x00000003 0x00000059>;
            phandle = <0x00000003>;
        };
        syscon@13030000 {
            compatible = "starfive,jh7110-sys-syscon", "syscon", "simple-mfd";
            reg = <0x00000000 0x13030000 0x00000000 0x00001000>;
            bootph-pre-ram;
            phandle = <0x0000001b>;
            clock-controller {
                compatible = "starfive,jh7110-pll";
                clocks = <0x00000020>;
                #clock-cells = <0x00000001>;
                bootph-pre-ram;
                phandle = <0x00000028>;
            };
        };
        pinctrl@13040000 {
            compatible = "starfive,jh7110-sys-pinctrl";
            reg = <0x00000000 0x13040000 0x00000000 0x00010000>;
            clocks = <0x00000003 0x00000070>;
            resets = <0x00000003 0x00000002>;
            interrupts = <0x00000056>;
            interrupt-controller;
            #interrupt-cells = <0x00000002>;
            gpio-controller;
            #gpio-cells = <0x00000002>;
            bootph-pre-ram;
            phandle = <0x0000002d>;
            i2c0-0 {
                phandle = <0x00000013>;
                i2c-pins {
                    pinmux = <0x09001439 0x0a00183a>;
                    bias-disable;
                    input-enable;
                    input-schmitt-enable;
                };
            };
            i2c2-0 {
                phandle = <0x00000014>;
                i2c-pins {
                    pinmux = <0x3b007803 0x3c007c02>;
                    bias-disable;
                    input-enable;
                    input-schmitt-enable;
                };
            };
            i2c5-0 {
                bootph-pre-ram;
                phandle = <0x00000021>;
                i2c-pins {
                    pinmux = <0x4f00a813 0x5000ac14>;
                    bias-disable;
                    input-enable;
                    input-schmitt-enable;
                    bootph-pre-ram;
                };
            };
            i2c6-0 {
                phandle = <0x00000022>;
                i2c-pins {
                    pinmux = <0x5600b810 0x5700bc11>;
                    bias-disable;
                    input-enable;
                    input-schmitt-enable;
                };
            };
            mmc0-0 {
                bootph-pre-ram;
                phandle = <0x0000002a>;
                rst-pins {
                    pinmux = <0xff13003e>;
                    bias-pull-up;
                    drive-strength = <0x0000000c>;
                    input-disable;
                    input-schmitt-disable;
                    slew-rate = <0x00000000>;
                    bootph-pre-ram;
                };
                mmc-pins {
                    pinmux = <0x00000440 0x00000441 0x00000442 0x00000443 0x00000444 0x00000445 0x00000446 0x00000447 0x00000448 0x00000449>;
                    bias-pull-up;
                    drive-strength = <0x0000000c>;
                    input-enable;
                };
            };
            mmc1-0 {
                bootph-pre-ram;
                phandle = <0x0000002e>;
                clk-pins {
                    pinmux = <0xff37000a>;
                    bias-pull-up;
                    drive-strength = <0x0000000c>;
                    input-disable;
                    input-schmitt-disable;
                    slew-rate = <0x00000000>;
                    bootph-pre-ram;
                };
                mmc-pins {
                    pinmux = <0x2c394c09 0x2d3a500b 0x2e3b540c 0x2f3c5807 0x303d5c08>;
                    bias-pull-up;
                    drive-strength = <0x0000000c>;
                    input-enable;
                    input-schmitt-enable;
                    slew-rate = <0x00000000>;
                    bootph-pre-ram;
                };
            };
            pcie0-0 {
                phandle = <0x00000040>;
                clkreq-pins {
                    pinmux = <0xff00041b>;
                    bias-pull-down;
                    drive-strength = <0x00000002>;
                    input-enable;
                    input-schmitt-disable;
                    slew-rate = <0x00000000>;
                };
                wake-pins {
                    pinmux = <0xff000420>;
                    bias-pull-up;
                    drive-strength = <0x00000002>;
                    input-enable;
                    input-schmitt-disable;
                    slew-rate = <0x00000000>;
                };
            };
            pcie1-0 {
                phandle = <0x00000043>;
                clkreq-pins {
                    pinmux = <0xff00041d>;
                    bias-pull-down;
                    drive-strength = <0x00000002>;
                    input-enable;
                    input-schmitt-disable;
                    slew-rate = <0x00000000>;
                };
                wake-pins {
                    pinmux = <0xff000415>;
                    bias-pull-up;
                    drive-strength = <0x00000002>;
                    input-enable;
                    input-schmitt-disable;
                    slew-rate = <0x00000000>;
                };
            };
            pwmdac-0 {
                phandle = <0x0000001c>;
                pwmdac-pins {
                    pinmux = <0xff1c0021 0xff1d0022>;
                    bias-disable;
                    drive-strength = <0x00000002>;
                    input-disable;
                    input-schmitt-disable;
                    slew-rate = <0x00000000>;
                };
            };
            pwm-0 {
                phandle = <0x00000025>;
                pwm-pins {
                    pinmux = <0xff18242e 0xff19283b>;
                    bias-disable;
                    drive-strength = <0x0000000c>;
                    input-disable;
                    input-schmitt-disable;
                    slew-rate = <0x00000000>;
                };
            };
            spi0-0 {
                phandle = <0x00000015>;
                mosi-pins {
                    pinmux = <0xff200034>;
                    bias-disable;
                    input-disable;
                    input-schmitt-disable;
                };
                miso-pins {
                    pinmux = <0x1c000435>;
                    bias-pull-up;
                    input-enable;
                    input-schmitt-enable;
                };
                sck-pins {
                    pinmux = <0x1a1e0030>;
                    bias-disable;
                    input-disable;
                    input-schmitt-disable;
                };
                ss-pins {
                    pinmux = <0x1b1f0031>;
                    bias-disable;
                    input-disable;
                    input-schmitt-disable;
                };
            };
            uart0-0 {
                phandle = <0x00000012>;
                tx-pins {
                    pinmux = <0xff140005>;
                    bias-disable;
                    drive-strength = <0x0000000c>;
                    input-disable;
                    input-schmitt-disable;
                    slew-rate = <0x00000000>;
                };
                rx-pins {
                    pinmux = <0x0e000406>;
                    bias-disable;
                    drive-strength = <0x00000002>;
                    input-enable;
                    input-schmitt-enable;
                    slew-rate = <0x00000000>;
                };
            };
        };
        watchdog@13070000 {
            compatible = "starfive,jh7110-wdt";
            reg = <0x00000000 0x13070000 0x00000000 0x00010000>;
            clocks = <0x00000003 0x0000007a 0x00000003 0x0000007b>;
            clock-names = "apb", "core";
            resets = <0x00000003 0x0000006d 0x00000003 0x0000006e>;
        };
        crypto@16000000 {
            compatible = "starfive,jh7110-crypto";
            reg = <0x00000000 0x16000000 0x00000000 0x00004000>;
            clocks = <0x0000001e 0x0000000f 0x0000001e 0x00000010>;
            clock-names = "hclk", "ahb";
            interrupts = <0x0000001c>;
            resets = <0x0000001e 0x00000003>;
            dmas = <0x00000029 0x00000001 0x00000002 0x00000029 0x00000000 0x00000002>;
            dma-names = "tx", "rx";
            phandle = <0x00000067>;
        };
        dma-controller@16008000 {
            compatible = "arm,pl080", "arm,primecell";
            arm,primecell-periphid = <0x00041080>;
            reg = <0x00000000 0x16008000 0x00000000 0x00004000>;
            interrupts = <0x0000001d>;
            clocks = <0x0000001e 0x0000000f>;
            clock-names = "apb_pclk";
            resets = <0x0000001e 0x00000003>;
            lli-bus-interface-ahb1;
            mem-bus-interface-ahb1;
            memcpy-burst-size = <0x00000100>;
            memcpy-bus-width = <0x00000020>;
            #dma-cells = <0x00000002>;
            phandle = <0x00000029>;
        };
        rng@1600c000 {
            compatible = "starfive,jh7110-trng";
            reg = <0x00000000 0x1600c000 0x00000000 0x00004000>;
            clocks = <0x0000001e 0x0000000f 0x0000001e 0x00000010>;
            clock-names = "hclk", "ahb";
            resets = <0x0000001e 0x00000003>;
            interrupts = <0x0000001e>;
            phandle = <0x00000068>;
        };
        mmc@16010000 {
            compatible = "starfive,jh7110-mmc";
            reg = <0x00000000 0x16010000 0x00000000 0x00010000>;
            clocks = <0x00000003 0x0000005b 0x00000003 0x0000005d>;
            clock-names = "biu", "ciu";
            resets = <0x00000003 0x00000040>;
            reset-names = "reset";
            interrupts = <0x0000004a>;
            fifo-depth = <0x00000020>;
            fifo-watermark-aligned;
            data-addr = <0x00000000>;
            starfive,sysreg = <0x0000001b 0x00000014 0x0000001a 0x7c000000>;
            status = "okay";
            max-frequency = <0x05f5e100>;
            assigned-clocks = <0x00000003 0x0000005d>;
            assigned-clock-rates = <0x02faf080>;
            bus-width = <0x00000008>;
            cap-mmc-highspeed;
            mmc-ddr-1_8v;
            mmc-hs200-1_8v;
            cap-mmc-hw-reset;
            post-power-on-delay-ms = <0x000000c8>;
            pinctrl-names = "default";
            pinctrl-0 = <0x0000002a>;
            vmmc-supply = <0x0000002b>;
            vqmmc-supply = <0x0000002c>;
            non-removable;
            bootph-pre-ram;
            phandle = <0x00000069>;
        };
        mmc@16020000 {
            compatible = "starfive,jh7110-mmc";
            reg = <0x00000000 0x16020000 0x00000000 0x00010000>;
            clocks = <0x00000003 0x0000005c 0x00000003 0x0000005e>;
            clock-names = "biu", "ciu";
            resets = <0x00000003 0x00000041>;
            reset-names = "reset";
            interrupts = <0x0000004b>;
            fifo-depth = <0x00000020>;
            fifo-watermark-aligned;
            data-addr = <0x00000000>;
            starfive,sysreg = <0x0000001b 0x0000009c 0x00000001 0x0000003e>;
            status = "okay";
            max-frequency = <0x05f5e100>;
            assigned-clocks = <0x00000003 0x0000005e>;
            assigned-clock-rates = <0x02faf080>;
            bus-width = <0x00000004>;
            no-sdio;
            no-mmc;
            cd-gpios = <0x0000002d 0x00000029 0x00000001>;
            disable-wp;
            cap-sd-highspeed;
            post-power-on-delay-ms = <0x000000c8>;
            pinctrl-names = "default";
            pinctrl-0 = <0x0000002e>;
            bootph-pre-ram;
            phandle = <0x0000006a>;
        };
        ethernet@16030000 {
            compatible = "starfive,jh7110-dwmac", "snps,dwmac-5.20";
            reg = <0x00000000 0x16030000 0x00000000 0x00010000>;
            clocks = <0x0000002f 0x00000003 0x0000002f 0x00000002 0x00000003 0x0000006d 0x0000002f 0x00000006 0x00000003 0x0000006f>;
            clock-names = "stmmaceth", "pclk", "ptp_ref", "tx", "gtx";
            resets = <0x0000002f 0x00000000 0x0000002f 0x00000001>;
            reset-names = "stmmaceth", "ahb";
            interrupts = <0x00000007 0x00000006 0x00000005>;
            interrupt-names = "macirq", "eth_wake_irq", "eth_lpi";
            rx-fifo-depth = <0x00000800>;
            tx-fifo-depth = <0x00000800>;
            snps,multicast-filter-bins = <0x00000040>;
            snps,perfect-filter-entries = <0x00000100>;
            snps,fixed-burst;
            snps,no-pbl-x8;
            snps,force_thresh_dma_mode;
            snps,axi-config = <0x00000030>;
            snps,tso;
            snps,txpbl = <0x00000010>;
            snps,rxpbl = <0x00000010>;
            starfive,syscon = <0x00000031 0x0000000c 0x00000012>;
            status = "okay";
            phy-handle = <0x00000032>;
            phy-mode = "rgmii-id";
            starfive,tx-use-rgmii-clk;
            assigned-clocks = <0x0000002f 0x00000005>;
            assigned-clock-parents = <0x0000002f 0x00000004>;
            phandle = <0x0000006b>;
            mdio {
                #address-cells = <0x00000001>;
                #size-cells = <0x00000000>;
                compatible = "snps,dwmac-mdio";
                ethernet-phy@0 {
                    reg = <0x00000000>;
                    motorcomm,tx-clk-adj-enabled;
                    motorcomm,tx-clk-100-inverted;
                    motorcomm,tx-clk-1000-inverted;
                    motorcomm,rx-clk-drv-microamp = <0x00000f82>;
                    motorcomm,rx-data-drv-microamp = <0x00000b5e>;
                    rx-internal-delay-ps = <0x000005dc>;
                    tx-internal-delay-ps = <0x000005dc>;
                    phandle = <0x00000032>;
                };
            };
        };
        ethernet@16040000 {
            compatible = "starfive,jh7110-dwmac", "snps,dwmac-5.20";
            reg = <0x00000000 0x16040000 0x00000000 0x00010000>;
            clocks = <0x00000003 0x00000062 0x00000003 0x00000061 0x00000003 0x00000066 0x00000003 0x0000006a 0x00000003 0x0000006b>;
            clock-names = "stmmaceth", "pclk", "ptp_ref", "tx", "gtx";
            resets = <0x00000003 0x00000042 0x00000003 0x00000043>;
            reset-names = "stmmaceth", "ahb";
            interrupts = <0x0000004e 0x0000004d 0x0000004c>;
            interrupt-names = "macirq", "eth_wake_irq", "eth_lpi";
            rx-fifo-depth = <0x00000800>;
            tx-fifo-depth = <0x00000800>;
            snps,multicast-filter-bins = <0x00000040>;
            snps,perfect-filter-entries = <0x00000100>;
            snps,fixed-burst;
            snps,no-pbl-x8;
            snps,force_thresh_dma_mode;
            snps,axi-config = <0x00000030>;
            snps,tso;
            snps,txpbl = <0x00000010>;
            snps,rxpbl = <0x00000010>;
            starfive,syscon = <0x0000001b 0x00000090 0x00000002>;
            status = "okay";
            phy-handle = <0x00000033>;
            phy-mode = "rgmii-id";
            starfive,tx-use-rgmii-clk;
            assigned-clocks = <0x00000003 0x00000069>;
            assigned-clock-parents = <0x00000003 0x00000065>;
            phandle = <0x0000006c>;
            mdio {
                #address-cells = <0x00000001>;
                #size-cells = <0x00000000>;
                compatible = "snps,dwmac-mdio";
                ethernet-phy@1 {
                    reg = <0x00000000>;
                    motorcomm,tx-clk-adj-enabled;
                    motorcomm,tx-clk-100-inverted;
                    motorcomm,rx-clk-drv-microamp = <0x00000f82>;
                    motorcomm,rx-data-drv-microamp = <0x00000b5e>;
                    rx-internal-delay-ps = <0x0000012c>;
                    tx-internal-delay-ps = <0x00000000>;
                    phandle = <0x00000033>;
                };
            };
        };
        dma-controller@16050000 {
            compatible = "starfive,jh7110-axi-dma";
            reg = <0x00000000 0x16050000 0x00000000 0x00010000>;
            clocks = <0x0000001e 0x0000001b 0x0000001e 0x0000001c>;
            clock-names = "core-clk", "cfgr-clk";
            resets = <0x0000001e 0x00000005 0x0000001e 0x00000006>;
            interrupts = <0x00000049>;
            #dma-cells = <0x00000001>;
            dma-channels = <0x00000004>;
            snps,dma-masters = <0x00000001>;
            snps,data-width = <0x00000003>;
            snps,block-size = <0x00010000 0x00010000 0x00010000 0x00010000>;
            snps,priority = <0x00000000 0x00000001 0x00000002 0x00000003>;
            snps,axi-max-burst-len = <0x00000010>;
            phandle = <0x00000017>;
        };
        clock-controller@17000000 {
            compatible = "starfive,jh7110-aoncrg";
            reg = <0x00000000 0x17000000 0x00000000 0x00010000>;
            clocks = <0x00000020 0x00000034 0x00000035 0x00000003 0x00000008 0x00000003 0x0000000b 0x00000003 0x0000006c 0x00000036>;
            clock-names = "osc", "gmac0_rmii_refin", "gmac0_rgmii_rxin", "stg_axiahb", "apb_bus", "gmac0_gtxclk", "rtc_osc";
            #clock-cells = <0x00000001>;
            #reset-cells = <0x00000001>;
            bootph-pre-ram;
            phandle = <0x0000002f>;
        };
        syscon@17010000 {
            compatible = "starfive,jh7110-aon-syscon", "syscon";
            reg = <0x00000000 0x17010000 0x00000000 0x00001000>;
            #power-domain-cells = <0x00000001>;
            phandle = <0x00000031>;
        };
        pinctrl@17020000 {
            compatible = "starfive,jh7110-aon-pinctrl";
            reg = <0x00000000 0x17020000 0x00000000 0x00010000>;
            resets = <0x0000002f 0x00000002>;
            interrupts = <0x00000055>;
            interrupt-controller;
            #interrupt-cells = <0x00000002>;
            gpio-controller;
            #gpio-cells = <0x00000002>;
            phandle = <0x0000006d>;
        };
        power-controller@17030000 {
            compatible = "starfive,jh7110-pmu";
            reg = <0x00000000 0x17030000 0x00000000 0x00010000>;
            interrupts = <0x0000006f>;
            #power-domain-cells = <0x00000001>;
            phandle = <0x0000003b>;
        };
        csi@19800000 {
            compatible = "starfive,jh7110-csi2rx", "cdns,csi2rx";
            reg = <0x00000000 0x19800000 0x00000000 0x00010000>;
            clocks = <0x00000037 0x00000007 0x00000037 0x00000006 0x00000037 0x00000008 0x00000037 0x00000009 0x00000037 0x0000000a 0x00000037 0x0000000b>;
            clock-names = "sys_clk", "p_clk", "pixel_if0_clk", "pixel_if1_clk", "pixel_if2_clk", "pixel_if3_clk";
            resets = <0x00000037 0x00000009 0x00000037 0x00000004 0x00000037 0x00000005 0x00000037 0x00000006 0x00000037 0x00000007 0x00000037 0x00000008>;
            reset-names = "sys", "reg_bank", "pixel_if0", "pixel_if1", "pixel_if2", "pixel_if3";
            phys = <0x00000038>;
            phy-names = "dphy";
            status = "disabled";
            assigned-clocks = <0x00000037 0x00000007>;
            assigned-clock-rates = <0x11b3dc40>;
            phandle = <0x0000006e>;
            ports {
                #address-cells = <0x00000001>;
                #size-cells = <0x00000000>;
                port@0 {
                    reg = <0x00000000>;
                };
                port@1 {
                    reg = <0x00000001>;
                    endpoint {
                        remote-endpoint = <0x00000039>;
                        phandle = <0x0000003c>;
                    };
                };
            };
        };
        clock-controller@19810000 {
            compatible = "starfive,jh7110-ispcrg";
            reg = <0x00000000 0x19810000 0x00000000 0x00010000>;
            clocks = <0x00000003 0x00000033 0x00000003 0x00000034 0x00000003 0x00000035 0x0000003a>;
            clock-names = "isp_top_core", "isp_top_axi", "noc_bus_isp_axi", "dvp_clk";
            resets = <0x00000003 0x00000029 0x00000003 0x0000002a 0x00000003 0x0000001c>;
            #clock-cells = <0x00000001>;
            #reset-cells = <0x00000001>;
            power-domains = <0x0000003b 0x00000005>;
            phandle = <0x00000037>;
        };
        phy@19820000 {
            compatible = "starfive,jh7110-dphy-rx";
            reg = <0x00000000 0x19820000 0x00000000 0x00010000>;
            clocks = <0x00000037 0x00000003 0x00000037 0x00000004 0x00000037 0x00000005>;
            clock-names = "cfg", "ref", "tx";
            resets = <0x00000037 0x00000002 0x00000037 0x00000003>;
            power-domains = <0x00000031 0x00000001>;
            #phy-cells = <0x00000000>;
            phandle = <0x00000038>;
        };
        isp@19840000 {
            compatible = "starfive,jh7110-camss";
            reg = <0x00000000 0x19840000 0x00000000 0x00010000 0x00000000 0x19870000 0x00000000 0x00030000>;
            reg-names = "syscon", "isp";
            clocks = <0x00000037 0x00000000 0x00000037 0x0000000d 0x00000037 0x00000002 0x00000037 0x0000000c 0x00000037 0x00000001 0x00000003 0x00000033 0x00000003 0x00000034>;
            clock-names = "apb_func", "wrapper_clk_c", "dvp_inv", "axiwr", "mipi_rx0_pxl", "ispcore_2x", "isp_axi";
            resets = <0x00000037 0x00000000 0x00000037 0x00000001 0x00000037 0x0000000a 0x00000037 0x0000000b 0x00000003 0x00000029 0x00000003 0x0000002a>;
            reset-names = "wrapper_p", "wrapper_c", "axird", "axiwr", "isp_top_n", "isp_top_axi";
            power-domains = <0x0000003b 0x00000005>;
            interrupts = <0x0000005c 0x00000057 0x0000005a 0x00000058>;
            status = "disabled";
            assigned-clocks = <0x00000037 0x00000000 0x00000037 0x00000001>;
            assigned-clock-rates = <0x02f34f60 0x0bcd3d80>;
            phandle = <0x0000006f>;
            ports {
                #address-cells = <0x00000001>;
                #size-cells = <0x00000000>;
                port@0 {
                    reg = <0x00000000>;
                };
                port@1 {
                    reg = <0x00000001>;
                    endpoint {
                        remote-endpoint = <0x0000003c>;
                        phandle = <0x00000039>;
                    };
                };
            };
        };
        clock-controller@295c0000 {
            compatible = "starfive,jh7110-voutcrg";
            reg = <0x00000000 0x295c0000 0x00000000 0x00010000>;
            clocks = <0x00000003 0x0000003a 0x00000003 0x0000003d 0x00000003 0x0000003e 0x00000003 0x0000003f 0x00000003 0x000000a5 0x0000003d>;
            clock-names = "vout_src", "vout_top_ahb", "vout_top_axi", "vout_top_hdmitx0_mclk", "i2stx0_bclk", "hdmitx0_pixelclk";
            resets = <0x00000003 0x0000002b>;
            #clock-cells = <0x00000001>;
            #reset-cells = <0x00000001>;
            power-domains = <0x0000003b 0x00000004>;
            phandle = <0x00000070>;
        };
        pcie@940000000 {
            compatible = "starfive,jh7110-pcie";
            reg = <0x00000009 0x40000000 0x00000000 0x01000000 0x00000000 0x2b000000 0x00000000 0x00100000>;
            reg-names = "cfg", "apb";
            linux,pci-domain = <0x00000000>;
            #address-cells = <0x00000003>;
            #size-cells = <0x00000002>;
            #interrupt-cells = <0x00000001>;
            ranges = <0x82000000 0x00000000 0x30000000 0x00000000 0x30000000 0x00000000 0x08000000 0xc3000000 0x00000009 0x00000000 0x00000009 0x00000000 0x00000000 0x40000000>;
            interrupts = <0x00000038>;
            interrupt-map-mask = <0x00000000 0x00000000 0x00000000 0x00000007>;
            interrupt-map = <0x00000000 0x00000000 0x00000000 0x00000001 0x0000003e 0x00000001 0x00000000 0x00000000 0x00000000 0x00000002 0x0000003e 0x00000002 0x00000000 0x00000000 0x00000000 0x00000003 0x0000003e 0x00000003 0x00000000 0x00000000 0x00000000 0x00000004 0x0000003e 0x00000004>;
            msi-controller;
            device_type = "pci";
            starfive,stg-syscon = <0x0000001d>;
            bus-range = <0x00000000 0x000000ff>;
            clocks = <0x00000003 0x00000060 0x0000001e 0x0000000a 0x0000001e 0x00000008 0x0000001e 0x00000009>;
            clock-names = "noc", "tl", "axi_mst0", "apb";
            resets = <0x0000001e 0x0000000b 0x0000001e 0x0000000c 0x0000001e 0x0000000d 0x0000001e 0x0000000e 0x0000001e 0x0000000f 0x0000001e 0x00000010>;
            reset-names = "mst0", "slv0", "slv", "brg", "core", "apb";
            status = "okay";
            perst-gpios = <0x0000002d 0x0000001a 0x00000001>;
            phys = <0x0000003f>;
            pinctrl-names = "default";
            pinctrl-0 = <0x00000040>;
            phandle = <0x00000071>;
            interrupt-controller {
                #address-cells = <0x00000000>;
                #interrupt-cells = <0x00000001>;
                interrupt-controller;
                phandle = <0x0000003e>;
            };
        };
        pcie@9c0000000 {
            compatible = "starfive,jh7110-pcie";
            reg = <0x00000009 0xc0000000 0x00000000 0x01000000 0x00000000 0x2c000000 0x00000000 0x00100000>;
            reg-names = "cfg", "apb";
            linux,pci-domain = <0x00000001>;
            #address-cells = <0x00000003>;
            #size-cells = <0x00000002>;
            #interrupt-cells = <0x00000001>;
            ranges = <0x82000000 0x00000000 0x38000000 0x00000000 0x38000000 0x00000000 0x08000000 0xc3000000 0x00000009 0x80000000 0x00000009 0x80000000 0x00000000 0x40000000>;
            interrupts = <0x00000039>;
            interrupt-map-mask = <0x00000000 0x00000000 0x00000000 0x00000007>;
            interrupt-map = <0x00000000 0x00000000 0x00000000 0x00000001 0x00000041 0x00000001 0x00000000 0x00000000 0x00000000 0x00000002 0x00000041 0x00000002 0x00000000 0x00000000 0x00000000 0x00000003 0x00000041 0x00000003 0x00000000 0x00000000 0x00000000 0x00000004 0x00000041 0x00000004>;
            msi-controller;
            device_type = "pci";
            starfive,stg-syscon = <0x0000001d>;
            bus-range = <0x00000000 0x000000ff>;
            clocks = <0x00000003 0x00000060 0x0000001e 0x0000000d 0x0000001e 0x0000000b 0x0000001e 0x0000000c>;
            clock-names = "noc", "tl", "axi_mst0", "apb";
            resets = <0x0000001e 0x00000011 0x0000001e 0x00000012 0x0000001e 0x00000013 0x0000001e 0x00000014 0x0000001e 0x00000015 0x0000001e 0x00000016>;
            reset-names = "mst0", "slv0", "slv", "brg", "core", "apb";
            status = "okay";
            perst-gpios = <0x0000002d 0x0000001c 0x00000001>;
            phys = <0x00000042>;
            pinctrl-names = "default";
            pinctrl-0 = <0x00000043>;
            phandle = <0x00000072>;
            interrupt-controller {
                #address-cells = <0x00000000>;
                #interrupt-cells = <0x00000001>;
                interrupt-controller;
                phandle = <0x00000041>;
            };
        };
        dmc@15700000 {
            bootph-pre-ram;
            compatible = "starfive,jh7110-dmc";
            reg = <0x00000000 0x15700000 0x00000000 0x00010000 0x00000000 0x13000000 0x00000000 0x00010000>;
            resets = <0x00000003 0x00000026 0x00000003 0x00000027 0x00000003 0x00000028>;
            reset-names = "axi", "osc", "apb";
            clocks = <0x00000003 0x00000001>;
            clock-names = "pll1_out";
            clock-frequency = <0x00000855>;
            phandle = <0x00000073>;
        };
    };
    aliases {
        ethernet0 = "/soc/ethernet@16030000";
        i2c0 = "/soc/i2c@10030000";
        i2c2 = "/soc/i2c@10050000";
        i2c5 = "/soc/i2c@12050000";
        i2c6 = "/soc/i2c@12060000";
        mmc0 = "/soc/mmc@16010000";
        mmc1 = "/soc/mmc@16020000";
        serial0 = "/soc/serial@10000000";
        ethernet1 = "/soc/ethernet@16040000";
        spi0 = "/soc/spi@13010000";
    };
    chosen {
        stdout-path = "serial0:115200n8";
        bootph-pre-ram;
    };
    memory@40000000 {
        device_type = "memory";
        reg = <0x00000000 0x40000000 0x00000001 0x00000000>;
        bootph-pre-ram;
    };
    gpio-restart {
        compatible = "gpio-restart";
        gpios = <0x0000002d 0x00000023 0x00000000>;
        priority = <0x000000e0>;
    };
    audio-codec {
        compatible = "linux,spdif-dit";
        #sound-dai-cells = <0x00000000>;
        phandle = <0x00000046>;
    };
    sound {
        compatible = "simple-audio-card";
        simple-audio-card,name = "StarFive-PWMDAC-Sound-Card";
        #address-cells = <0x00000001>;
        #size-cells = <0x00000000>;
        simple-audio-card,dai-link@0 {
            reg = <0x00000000>;
            format = "left_j";
            bitclock-master = <0x00000044>;
            frame-master = <0x00000044>;
            cpu {
                sound-dai = <0x00000045>;
                phandle = <0x00000044>;
            };
            codec {
                sound-dai = <0x00000046>;
            };
        };
    };
    timer {
        compatible = "riscv,timer";
        interrupts-extended = <0x0000000d 0x00000005 0x0000000e 0x00000005 0x0000000f 0x00000005 0x00000010 0x00000005 0x00000011 0x00000005>;
    };
    firmware {
        spi0 = "/soc/spi@13010000";
        bootph-pre-ram;
    };
    binman {
        multiple-images;
        phandle = <0x00000074>;
        itb {
            filename = "u-boot.itb";
            fit {
                description = "Configuration to load OpenSBI before U-Boot";
                #address-cells = <0x00000002>;
                fit,fdt-list = "of-list";
                images {
                    uboot {
                        description = "U-Boot";
                        type = "standalone";
                        os = "U-Boot";
                        arch = "riscv";
                        compression = "none";
                        load = <0x00000000 0x40200000>;
                        u-boot-nodtb {
                            phandle = <0x00000075>;
                        };
                    };
                    opensbi {
                        description = "OpenSBI fw_dynamic Firmware";
                        type = "firmware";
                        os = "opensbi";
                        arch = "riscv";
                        compression = "none";
                        load = <0x00000000 0x40000000>;
                        entry = <0x00000000 0x40000000>;
                        opensbi {
                            filename = "fw_dynamic.bin";
                            missing-msg = "opensbi";
                            phandle = <0x00000076>;
                        };
                    };
                    @fdt-SEQ {
                        fit,operation = "gen-fdt-nodes";
                        description = "NAME";
                        type = "flat_dt";
                        compression = "none";
                    };
                };
                configurations {
                    @conf-SEQ {
                        description = "NAME";
                        firmware = "opensbi";
                        loadables = "uboot";
                        fdt = "fdt-SEQ";
                    };
                };
            };
        };
        spl-img {
            filename = "spl/u-boot-spl.bin.normal.out";
            mkimage {
                args = "-T sfspl";
                u-boot-spl {
                    no-write-symbols;
                };
            };
        };
    };
    config {
        bootph-pre-ram;
        u-boot,spl-payload-offset = <0x00100000>;
    };
    __symbols__ {
        cpus = "/cpus";
        S7_0 = "/cpus/cpu@0";
        cpu0_intc = "/cpus/cpu@0/interrupt-controller";
        U74_1 = "/cpus/cpu@1";
        cpu1_intc = "/cpus/cpu@1/interrupt-controller";
        U74_2 = "/cpus/cpu@2";
        cpu2_intc = "/cpus/cpu@2/interrupt-controller";
        U74_3 = "/cpus/cpu@3";
        cpu3_intc = "/cpus/cpu@3/interrupt-controller";
        U74_4 = "/cpus/cpu@4";
        cpu4_intc = "/cpus/cpu@4/interrupt-controller";
        cpu_opp = "/opp-table-0";
        cpu_alert0 = "/thermal-zones/cpu-thermal/trips/cpu-alert0";
        dvp_clk = "/dvp-clock";
        gmac0_rgmii_rxin = "/gmac0-rgmii-rxin-clock";
        gmac0_rmii_refin = "/gmac0-rmii-refin-clock";
        gmac1_rgmii_rxin = "/gmac1-rgmii-rxin-clock";
        gmac1_rmii_refin = "/gmac1-rmii-refin-clock";
        hdmitx0_pixelclk = "/hdmitx0-pixel-clock";
        i2srx_bclk_ext = "/i2srx-bclk-ext-clock";
        i2srx_lrck_ext = "/i2srx-lrck-ext-clock";
        i2stx_bclk_ext = "/i2stx-bclk-ext-clock";
        i2stx_lrck_ext = "/i2stx-lrck-ext-clock";
        mclk_ext = "/mclk-ext-clock";
        osc = "/oscillator";
        rtc_osc = "/rtc-oscillator";
        stmmac_axi_setup = "/stmmac-axi-config";
        tdm_ext = "/tdm-ext-clock";
        clint = "/soc/timer@2000000";
        ccache = "/soc/cache-controller@2010000";
        plic = "/soc/interrupt-controller@c000000";
        uart0 = "/soc/serial@10000000";
        uart1 = "/soc/serial@10010000";
        uart2 = "/soc/serial@10020000";
        i2c0 = "/soc/i2c@10030000";
        i2c1 = "/soc/i2c@10040000";
        i2c2 = "/soc/i2c@10050000";
        spi0 = "/soc/spi@10060000";
        spi1 = "/soc/spi@10070000";
        spi2 = "/soc/spi@10080000";
        tdm = "/soc/tdm@10090000";
        i2srx = "/soc/i2s@100e0000";
        pwmdac = "/soc/pwmdac@100b0000";
        usb0 = "/soc/usb@10100000";
        usb_cdns3 = "/soc/usb@10100000/usb@0";
        usbphy0 = "/soc/phy@10200000";
        pciephy0 = "/soc/phy@10210000";
        pciephy1 = "/soc/phy@10220000";
        stgcrg = "/soc/clock-controller@10230000";
        stg_syscon = "/soc/syscon@10240000";
        uart3 = "/soc/serial@12000000";
        uart4 = "/soc/serial@12010000";
        uart5 = "/soc/serial@12020000";
        i2c3 = "/soc/i2c@12030000";
        i2c4 = "/soc/i2c@12040000";
        i2c5 = "/soc/i2c@12050000";
        axp15060 = "/soc/i2c@12050000/pmic@36";
        vcc_3v3 = "/soc/i2c@12050000/pmic@36/regulators/dcdc1";
        vdd_cpu = "/soc/i2c@12050000/pmic@36/regulators/dcdc2";
        emmc_vdd = "/soc/i2c@12050000/pmic@36/regulators/aldo4";
        i2c6 = "/soc/i2c@12060000";
        spi3 = "/soc/spi@12070000";
        spi4 = "/soc/spi@12080000";
        spi5 = "/soc/spi@12090000";
        spi6 = "/soc/spi@120a0000";
        i2stx0 = "/soc/i2s@120b0000";
        i2stx1 = "/soc/i2s@120c0000";
        pwm = "/soc/pwm@120d0000";
        sfctemp = "/soc/temperature-sensor@120e0000";
        qspi = "/soc/spi@13010000";
        nor_flash = "/soc/spi@13010000/flash@0";
        syscrg = "/soc/clock-controller@13020000";
        sys_syscon = "/soc/syscon@13030000";
        pllclk = "/soc/syscon@13030000/clock-controller";
        sysgpio = "/soc/pinctrl@13040000";
        i2c0_pins = "/soc/pinctrl@13040000/i2c0-0";
        i2c2_pins = "/soc/pinctrl@13040000/i2c2-0";
        i2c5_pins = "/soc/pinctrl@13040000/i2c5-0";
        i2c6_pins = "/soc/pinctrl@13040000/i2c6-0";
        mmc0_pins = "/soc/pinctrl@13040000/mmc0-0";
        mmc1_pins = "/soc/pinctrl@13040000/mmc1-0";
        pcie0_pins = "/soc/pinctrl@13040000/pcie0-0";
        pcie1_pins = "/soc/pinctrl@13040000/pcie1-0";
        pwmdac_pins = "/soc/pinctrl@13040000/pwmdac-0";
        pwm_pins = "/soc/pinctrl@13040000/pwm-0";
        spi0_pins = "/soc/pinctrl@13040000/spi0-0";
        uart0_pins = "/soc/pinctrl@13040000/uart0-0";
        crypto = "/soc/crypto@16000000";
        sdma = "/soc/dma-controller@16008000";
        rng = "/soc/rng@1600c000";
        mmc0 = "/soc/mmc@16010000";
        mmc1 = "/soc/mmc@16020000";
        gmac0 = "/soc/ethernet@16030000";
        phy0 = "/soc/ethernet@16030000/mdio/ethernet-phy@0";
        gmac1 = "/soc/ethernet@16040000";
        phy1 = "/soc/ethernet@16040000/mdio/ethernet-phy@1";
        dma = "/soc/dma-controller@16050000";
        aoncrg = "/soc/clock-controller@17000000";
        aon_syscon = "/soc/syscon@17010000";
        aongpio = "/soc/pinctrl@17020000";
        pwrc = "/soc/power-controller@17030000";
        csi2rx = "/soc/csi@19800000";
        csi2rx_to_camss = "/soc/csi@19800000/ports/port@1/endpoint";
        ispcrg = "/soc/clock-controller@19810000";
        csi_phy = "/soc/phy@19820000";
        camss = "/soc/isp@19840000";
        camss_from_csi2rx = "/soc/isp@19840000/ports/port@1/endpoint";
        voutcrg = "/soc/clock-controller@295c0000";
        pcie0 = "/soc/pcie@940000000";
        pcie_intc0 = "/soc/pcie@940000000/interrupt-controller";
        pcie1 = "/soc/pcie@9c0000000";
        pcie_intc1 = "/soc/pcie@9c0000000/interrupt-controller";
        dmc = "/soc/dmc@15700000";
        pwmdac_codec = "/audio-codec";
        sndcpu0 = "/sound/simple-audio-card,dai-link@0/cpu";
        binman = "/binman";
        uboot_blob = "/binman/itb/fit/images/uboot/u-boot-nodtb";
        opensbi_blob = "/binman/itb/fit/images/opensbi/opensbi";
    };
};
